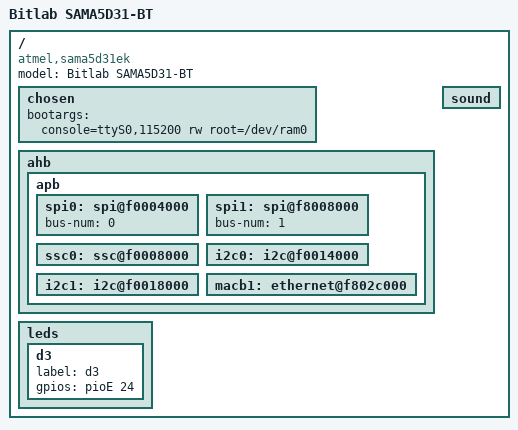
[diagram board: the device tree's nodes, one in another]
/*
 * sama5d31bt.dts - Device Tree file for SAMA5-BT board
 *
 *  Copyright (C) 2013 Bitlab Pty Ltd,
 *
 * Licensed under GPLv2 or later.
 */
/dts-v1/;
/include/ "sama5d3mb.dtsi"
/include/ "sama5d3dm.dtsi"

/ {
	model = "Bitlab SAMA5D31-BT";
	compatible = "atmel,sama5d31ek", "atmel,sama5ek", "atmel,sama5d3", "atmel,sama5";

	chosen {
		bootargs = "console=ttyS0,115200 rw root=/dev/ram0";
	};

	ahb {
		apb {
			spi0: spi@f0004000 {
				bus-num = <0>;
				status = "okay";
			};

			spi1: spi@f8008000 {
				bus-num = <1>;
				status = "okay";
			};

			ssc0: ssc@f0008000 {
				status = "okay";
			};

			i2c0: i2c@f0014000 {
				status = "okay";
			};

			i2c1: i2c@f0018000 {
				status = "okay";
			};

			macb1: ethernet@f802c000 {
				status = "okay";
			};
		};
	};

	leds {
		d3 {
			label = "d3";
			gpios = <&pioE 24 0>;
		};
	};

	sound {
		status = "okay";
	};
};
